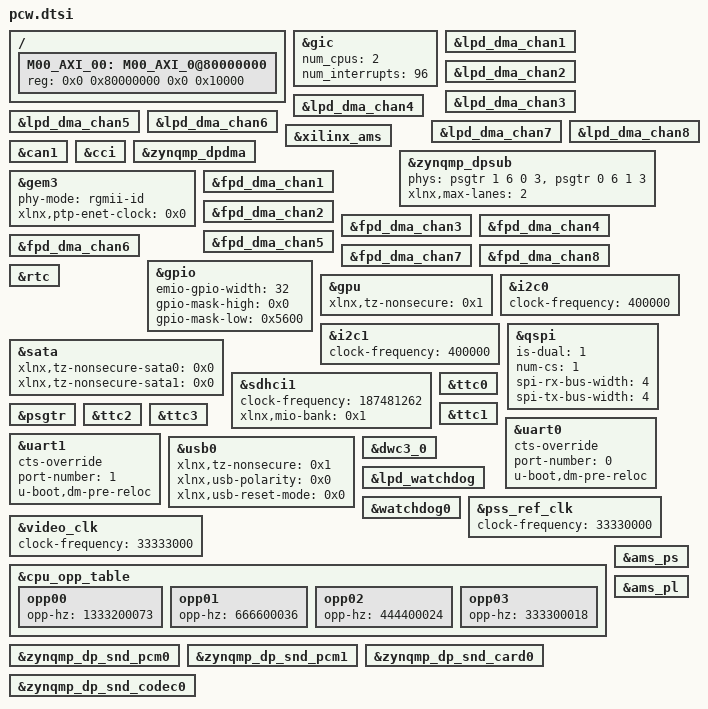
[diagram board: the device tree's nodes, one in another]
/*
 * CAUTION: This file is automatically generated by Xilinx.
 * Version: XSCT 2022.2
 * Today is: Tue Dec 16 06:17:22 2025
 */


&gic {
	num_cpus = <2>;
	num_interrupts = <96>;
};
&lpd_dma_chan1 {
	status = "okay";
};
&lpd_dma_chan2 {
	status = "okay";
};
&lpd_dma_chan3 {
	status = "okay";
};
&lpd_dma_chan4 {
	status = "okay";
};
&lpd_dma_chan5 {
	status = "okay";
};
&lpd_dma_chan6 {
	status = "okay";
};
&lpd_dma_chan7 {
	status = "okay";
};
&lpd_dma_chan8 {
	status = "okay";
};
&xilinx_ams {
	status = "okay";
};
&can1 {
	status = "okay";
};
&cci {
	status = "okay";
};
&zynqmp_dpsub {
	phy-names = "dp-phy0","dp-phy1";
	phys = <&psgtr 1 6 0 3>, <&psgtr 0 6 1 3>;
	status = "okay";
	xlnx,max-lanes = <2>;
};
&zynqmp_dpdma {
	status = "okay";
};
&gem3 {
	phy-mode = "rgmii-id";
	status = "okay";
	xlnx,ptp-enet-clock = <0x0>;
};
&fpd_dma_chan1 {
	status = "okay";
};
&fpd_dma_chan2 {
	status = "okay";
};
&fpd_dma_chan3 {
	status = "okay";
};
&fpd_dma_chan4 {
	status = "okay";
};
&fpd_dma_chan5 {
	status = "okay";
};
&fpd_dma_chan6 {
	status = "okay";
};
&fpd_dma_chan7 {
	status = "okay";
};
&fpd_dma_chan8 {
	status = "okay";
};
&gpio {
	emio-gpio-width = <32>;
	gpio-mask-high = <0x0>;
	gpio-mask-low = <0x5600>;
	status = "okay";
};
&gpu {
	status = "okay";
	xlnx,tz-nonsecure = <0x1>;
};
&i2c0 {
	clock-frequency = <400000>;
	status = "okay";
};
&i2c1 {
	clock-frequency = <400000>;
	status = "okay";
};
&qspi {
	is-dual = <1>;
	num-cs = <1>;
	spi-rx-bus-width = <4>;
	spi-tx-bus-width = <4>;
	status = "okay";
};
&rtc {
	status = "okay";
};
&sata {
	status = "okay";
	xlnx,tz-nonsecure-sata0 = <0x0>;
	xlnx,tz-nonsecure-sata1 = <0x0>;
};
&sdhci1 {
	clock-frequency = <187481262>;
	status = "okay";
	xlnx,mio-bank = <0x1>;
};
&psgtr {
	status = "okay";
};
&ttc0 {
	status = "okay";
};
&ttc1 {
	status = "okay";
};
&ttc2 {
	status = "okay";
};
&ttc3 {
	status = "okay";
};
&uart0 {
	cts-override ;
	device_type = "serial";
	port-number = <0>;
	status = "okay";
	u-boot,dm-pre-reloc ;
};
&uart1 {
	cts-override ;
	device_type = "serial";
	port-number = <1>;
	status = "okay";
	u-boot,dm-pre-reloc ;
};
&usb0 {
	status = "okay";
	xlnx,tz-nonsecure = <0x1>;
	xlnx,usb-polarity = <0x0>;
	xlnx,usb-reset-mode = <0x0>;
};
&dwc3_0 {
	status = "okay";
};
&lpd_watchdog {
	status = "okay";
};
&watchdog0 {
	status = "okay";
};
&pss_ref_clk {
	clock-frequency = <33330000>;
};
&video_clk {
	clock-frequency = <33333000>;
};
&cpu_opp_table {
	opp00 {
		opp-hz = /bits/ 64 <1333200073>;
	};
	opp01 {
		opp-hz = /bits/ 64 <666600036>;
	};
	opp02 {
		opp-hz = /bits/ 64 <444400024>;
	};
	opp03 {
		opp-hz = /bits/ 64 <333300018>;
	};
};
/ {
	M00_AXI_00: M00_AXI_0@80000000 {
		/* This is a external AXI interface, user may need to update the entries */
		reg = <0x0 0x80000000 0x0 0x10000>;
	};
};
&ams_ps {
	status = "okay";
};
&ams_pl {
	status = "okay";
};
&zynqmp_dp_snd_pcm0 {
	status = "okay";
};
&zynqmp_dp_snd_pcm1 {
	status = "okay";
};
&zynqmp_dp_snd_card0 {
	status = "okay";
};
&zynqmp_dp_snd_codec0 {
	status = "okay";
};
